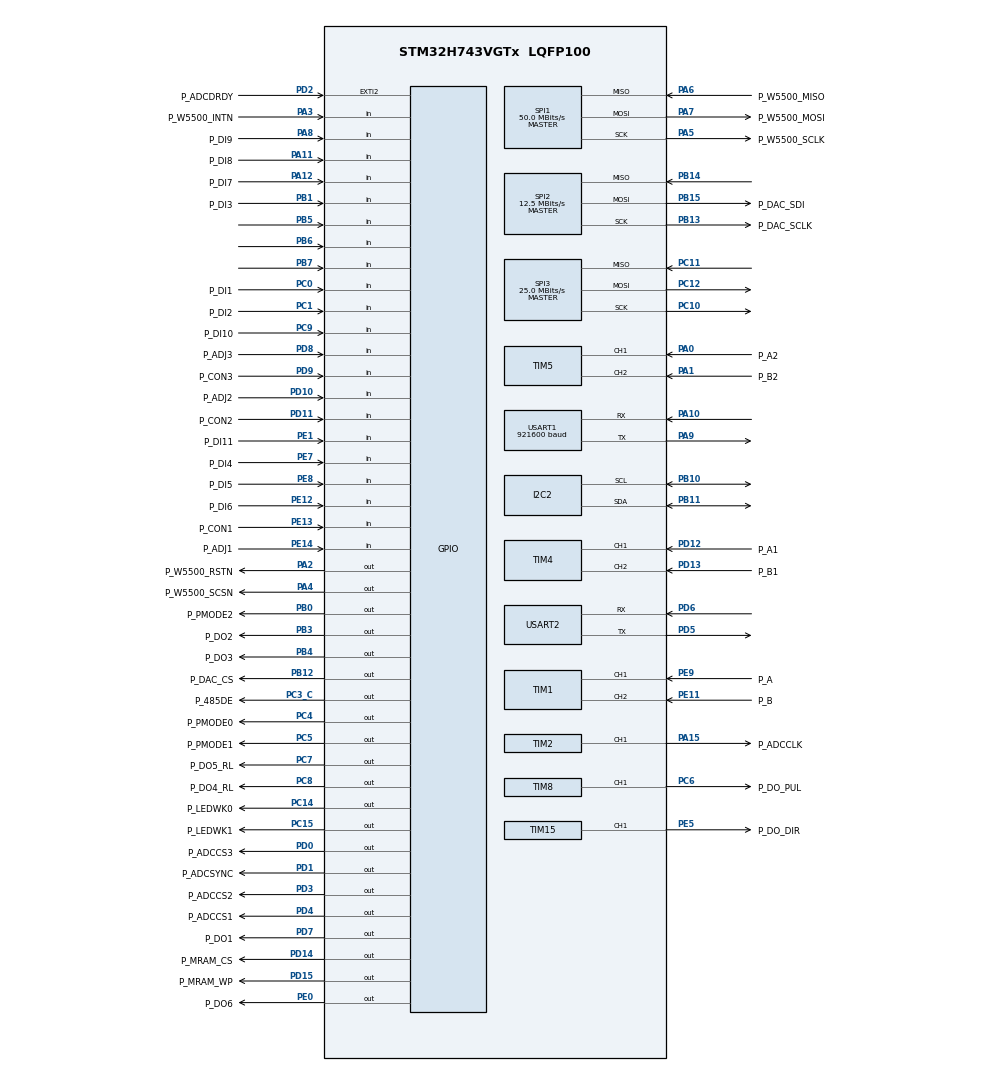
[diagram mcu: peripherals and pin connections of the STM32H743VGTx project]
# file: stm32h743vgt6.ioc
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CORTEX_M7.CPU_DCache=Disabled
CORTEX_M7.CPU_ICache=Disabled
CORTEX_M7.MPU_Control=MPU_PRIVILEGED_DEFAULT
CORTEX_M7.default_mode_Activation=1
FREERTOS.BinarySemaphores01=cs5552Sem,Dynamic,NULL,Available
FREERTOS.MEMORY_ALLOCATION=0
FREERTOS.Mutexes01=Controller_statusMutex,Dynamic,NULL;pgMutex,Dynamic,NULL;moveparaMutex,Dynamic,NULL
FREERTOS.Queues01=lpusTANQueue,16,uint16_t,0,Dynamic,NULL,NULL
FREERTOS.Tasks01=defaultTask,0,128,StartDefaultTask,Default,NULL,Dynamic,NULL,NULL;loopTask,3,2048,LoopTask,Default,NULL,Dynamic,NULL,NULL;watchdogTask,-2,128,WatchdogTask,Default,NULL,Dynamic,NULL,NULL;comTask,0,512,CommuicationTask,Default,NULL,Dynamic,NULL,NULL;waveTask,2,256,WaveTask,Default,NULL,Dynamic,NULL,NULL;ethernetTask,0,1024,EthernetTask,Default,NULL,Dynamic,NULL,NULL;cdatatranstask,0,256,CDataTransTask,Default,NULL,Dynamic,NULL,NULL;eepromTask,-2,512,EepromTask,Default,NULL,Dynamic,NULL,NULL
FREERTOS.configGENERATE_RUN_TIME_STATS=1
FREERTOS.configIDLE_SHOULD_YIELD=0
FREERTOS.configMAX_PRIORITIES=32
FREERTOS.configTOTAL_HEAP_SIZE=32768
FREERTOS.configUSE_STATS_FORMATTING_FUNCTIONS=1
FREERTOS.configUSE_TRACE_FACILITY=1
I2C2.Timing=0x10C0ECFF
Mcu.Family=STM32H7
Mcu.Name=STM32H743VGTx
Mcu.Package=LQFP100
NVIC.PriorityGroup=NVIC_PRIORITYGROUP_4
NVIC.TIM16_IRQn=true\:5\:0\:true\:false\:true\:true\:true\:true\:true
NVIC.TIM17_IRQn=true\:5\:0\:true\:false\:true\:true\:true\:true\:true
NVIC.TIM6_DAC_IRQn=true\:5\:0\:false\:false\:true\:true\:true\:true\:true
NVIC.TIM7_IRQn=true\:15\:0\:true\:false\:true\:false\:false\:true\:true
NVIC.TIM8_CC_IRQn=true\:5\:0\:false\:false\:true\:true\:true\:true\:true
NVIC.TimeBase=TIM7_IRQn
NVIC.TimeBaseIP=TIM7
NVIC.USART2_IRQn=true\:5\:0\:false\:false\:true\:true\:true\:true\:true
PA0.GPIO_Label=P_A2
PA0.Signal=S_TIM5_CH1
PA1.GPIO_Label=P_B2
PA1.Signal=S_TIM5_CH2
PA10.Mode=Asynchronous
PA10.Signal=USART1_RX
PA11.GPIO_Label=P_DI8
PA11.Signal=GPIO_Input
PA12.GPIO_Label=P_DI7
PA12.Signal=GPIO_Input
PA13\ (JTMS/SWDIO).Mode=Serial_Wire
PA13\ (JTMS/SWDIO).Signal=DEBUG_JTMS-SWDIO
PA14\ (JTCK/SWCLK).Mode=Serial_Wire
PA14\ (JTCK/SWCLK).Signal=DEBUG_JTCK-SWCLK
PA15\ (JTDI).GPIO_Label=P_ADCCLK
PA15\ (JTDI).Signal=S_TIM2_CH1_ETR
PA2.GPIO_Label=P_W5500_RSTN
PA2.Signal=GPIO_Output
PA3.GPIO_Label=P_W5500_INTN
PA3.Signal=GPIO_Input
PA4.GPIO_Label=P_W5500_SCSN
PA4.Signal=GPIO_Output
PA5.GPIO_Label=P_W5500_SCLK
PA5.GPIO_Speed=GPIO_SPEED_FREQ_VERY_HIGH
PA5.Mode=Full_Duplex_Master
PA5.Signal=SPI1_SCK
PA6.GPIO_Label=P_W5500_MISO
PA6.GPIO_Speed=GPIO_SPEED_FREQ_VERY_HIGH
PA6.Mode=Full_Duplex_Master
PA6.Signal=SPI1_MISO
PA7.GPIO_Label=P_W5500_MOSI
PA7.GPIO_Speed=GPIO_SPEED_FREQ_VERY_HIGH
PA7.Mode=Full_Duplex_Master
PA7.Signal=SPI1_MOSI
PA8.GPIO_Label=P_DI9
PA8.Signal=GPIO_Input
PA9.Mode=Asynchronous
PA9.Signal=USART1_TX
PB0.GPIO_Label=P_PMODE2
PB0.Signal=GPIO_Output
PB1.GPIO_Label=P_DI3
PB1.Signal=GPIO_Input
PB10.GPIO_Speed=GPIO_SPEED_FREQ_HIGH
PB10.Mode=I2C
PB10.Signal=I2C2_SCL
PB11.GPIO_Speed=GPIO_SPEED_FREQ_HIGH
PB11.Mode=I2C
PB11.Signal=I2C2_SDA
PB12.GPIO_Label=P_DAC_CS
PB12.GPIO_Speed=GPIO_SPEED_FREQ_HIGH
PB12.PinState=GPIO_PIN_SET
PB12.Signal=GPIO_Output
PB13.GPIO_Label=P_DAC_SCLK
PB13.Mode=Full_Duplex_Master
PB13.Signal=SPI2_SCK
PB14.Mode=Full_Duplex_Master
PB14.Signal=SPI2_MISO
PB15.GPIO_Label=P_DAC_SDI
PB15.Mode=Full_Duplex_Master
PB15.Signal=SPI2_MOSI
PB3\ (JTDO/TRACESWO).GPIO_Label=P_DO2
PB3\ (JTDO/TRACESWO).Signal=GPIO_Output
PB4\ (NJTRST).GPIO_Label=P_DO3
PB4\ (NJTRST).Signal=GPIO_Output
PB5.Signal=GPIO_Input
PB6.Signal=GPIO_Input
PB7.Signal=GPIO_Input
PC0.GPIO_Label=P_DI1
PC0.Signal=GPIO_Input
PC1.GPIO_Label=P_DI2
PC1.Signal=GPIO_Input
PC10.Mode=Full_Duplex_Master
PC10.Signal=SPI3_SCK
PC11.Mode=Full_Duplex_Master
PC11.Signal=SPI3_MISO
PC12.Mode=Full_Duplex_Master
PC12.Signal=SPI3_MOSI
PC14-OSC32_IN\ (OSC32_IN).GPIO_Label=P_LEDWK0
PC14-OSC32_IN\ (OSC32_IN).Signal=GPIO_Output
PC15-OSC32_OUT\ (OSC32_OUT).GPIO_Label=P_LEDWK1
PC15-OSC32_OUT\ (OSC32_OUT).Signal=GPIO_Output
PC3_C.GPIO_Label=P_485DE
PC3_C.Signal=GPIO_Output
PC4.GPIO_Label=P_PMODE0
PC4.Signal=GPIO_Output
PC5.GPIO_Label=P_PMODE1
PC5.GPIO_PuPd=GPIO_PULLUP
PC5.PinState=GPIO_PIN_SET
PC5.Signal=GPIO_Output
PC6.GPIO_Label=P_DO_PUL
PC6.GPIO_Speed=GPIO_SPEED_FREQ_VERY_HIGH
PC6.Signal=S_TIM8_CH1
PC7.GPIO_Label=P_DO5_RL
PC7.Signal=GPIO_Output
PC8.GPIO_Label=P_DO4_RL
PC8.Signal=GPIO_Output
PC9.GPIO_Label=P_DI10
PC9.Signal=GPIO_Input
PD0.GPIO_Label=P_ADCCS3
PD0.GPIO_Speed=GPIO_SPEED_FREQ_HIGH
PD0.PinState=GPIO_PIN_SET
PD0.Signal=GPIO_Output
PD1.GPIO_Label=P_ADCSYNC
PD1.Signal=GPIO_Output
PD10.GPIO_Label=P_ADJ2
PD10.Signal=GPIO_Input
PD11.GPIO_Label=P_CON2
PD11.Signal=GPIO_Input
PD12.GPIO_Label=P_A1
PD12.Signal=S_TIM4_CH1
PD13.GPIO_Label=P_B1
PD13.Signal=S_TIM4_CH2
PD14.GPIO_Label=P_MRAM_CS
PD14.GPIO_Speed=GPIO_SPEED_FREQ_HIGH
PD14.PinState=GPIO_PIN_SET
PD14.Signal=GPIO_Output
PD15.GPIO_Label=P_MRAM_WP
PD15.GPIO_Speed=GPIO_SPEED_FREQ_HIGH
PD15.PinState=GPIO_PIN_SET
PD15.Signal=GPIO_Output
PD2.GPIO_Label=P_ADCDRDY
PD2.GPIO_ModeDefaultEXTI=GPIO_MODE_IT_FALLING
PD2.Signal=GPXTI2
PD3.GPIO_Label=P_ADCCS2
PD3.GPIO_Speed=GPIO_SPEED_FREQ_HIGH
PD3.PinState=GPIO_PIN_SET
PD3.Signal=GPIO_Output
PD4.GPIO_Label=P_ADCCS1
PD4.GPIO_Speed=GPIO_SPEED_FREQ_HIGH
PD4.PinState=GPIO_PIN_SET
PD4.Signal=GPIO_Output
PD5.Mode=Asynchronous
PD5.Signal=USART2_TX
PD6.Mode=Asynchronous
PD6.Signal=USART2_RX
PD7.GPIO_Label=P_DO1
PD7.Signal=GPIO_Output
PD8.GPIO_Label=P_ADJ3
PD8.Signal=GPIO_Input
PD9.GPIO_Label=P_CON3
PD9.Signal=GPIO_Input
PE0.GPIO_Label=P_DO6
PE0.Signal=GPIO_Output
PE1.GPIO_Label=P_DI11
PE1.GPIO_PuPd=GPIO_PULLUP
PE1.Signal=GPIO_Input
PE11.GPIO_Label=P_B
PE11.Signal=S_TIM1_CH2
PE12.GPIO_Label=P_DI6
PE12.Signal=GPIO_Input
PE13.GPIO_Label=P_CON1
PE13.Signal=GPIO_Input
PE14.GPIO_Label=P_ADJ1
PE14.Signal=GPIO_Input
PE5.GPIO_Label=P_DO_DIR
PE5.GPIO_Speed=GPIO_SPEED_FREQ_VERY_HIGH
PE5.Signal=S_TIM15_CH1
PE7.GPIO_Label=P_DI4
PE7.Signal=GPIO_Input
PE8.GPIO_Label=P_DI5
PE8.Signal=GPIO_Input
PE9.GPIO_Label=P_A
PE9.Signal=S_TIM1_CH1
PH0-OSC_IN\ (PH0).Mode=HSE-External-Oscillator
PH0-OSC_IN\ (PH0).Signal=RCC_OSC_IN
PH1-OSC_OUT\ (PH1).Mode=HSE-External-Oscillator
PH1-OSC_OUT\ (PH1).Signal=RCC_OSC_OUT
ProjectManager.HeapSize=0x1000
ProjectManager.StackSize=0x1000
ProjectManager.TargetToolchain=MDK-ARM V5
RCC.ADCFreq_Value=16125000
RCC.APB1Freq_Value=100000000
RCC.APB2Freq_Value=100000000
RCC.APB3Freq_Value=100000000
RCC.APB4Freq_Value=100000000
RCC.CortexFreq_Value=200000000
RCC.D1PPRE=RCC_APB3_DIV2
RCC.D2PPRE1=RCC_APB1_DIV2
RCC.D2PPRE2=RCC_APB2_DIV2
RCC.D3PPRE=RCC_APB4_DIV2
RCC.DIVM1=1
RCC.DIVN1=50
RCC.HCLKFreq_Value=200000000
RCC.HSE_VALUE=8000000
RCC.PLL2FRACN=0
RCC.PLL3FRACN=0
RCC.PLLFRACN=0
RCC.PLLSourceVirtual=RCC_PLLSOURCE_HSE
RCC.PWR_Regulator_Voltage_Scale=PWR_REGULATOR_VOLTAGE_SCALE0
RCC.ProductRev=revV
RCC.SYSCLKFreq_VALUE=200000000
RCC.SYSCLKSource=RCC_SYSCLKSOURCE_PLLCLK
RCC.SupplySource=PWR_LDO_SUPPLY
RCC.USBFreq_Value=200000000
SH.S_TIM15_CH1.0=TIM15_CH1,PWM Generation1 CH1
SH.S_TIM1_CH1.0=TIM1_CH1,Encoder_Interface
SH.S_TIM1_CH2.0=TIM1_CH2,Encoder_Interface
SH.S_TIM2_CH1_ETR.0=TIM2_CH1,PWM Generation1 CH1
SH.S_TIM4_CH1.0=TIM4_CH1,Encoder_Interface
SH.S_TIM4_CH2.0=TIM4_CH2,Encoder_Interface
SH.S_TIM5_CH1.0=TIM5_CH1,Encoder_Interface
SH.S_TIM5_CH2.0=TIM5_CH2,Encoder_Interface
SH.S_TIM8_CH1.0=TIM8_CH1,PWM Generation1 CH1
SPI1.BaudRatePrescaler=SPI_BAUDRATEPRESCALER_4
SPI1.CalculateBaudRate=50.0 MBits/s
SPI1.DataSize=SPI_DATASIZE_8BIT
SPI1.Direction=SPI_DIRECTION_2LINES
SPI1.Mode=SPI_MODE_MASTER
SPI1.NSSPMode=SPI_NSS_PULSE_DISABLE
SPI1.VirtualType=VM_MASTER
SPI2.BaudRatePrescaler=SPI_BAUDRATEPRESCALER_16
SPI2.CalculateBaudRate=12.5 MBits/s
SPI2.DataSize=SPI_DATASIZE_8BIT
SPI2.Direction=SPI_DIRECTION_2LINES
SPI2.Mode=SPI_MODE_MASTER
SPI2.VirtualType=VM_MASTER
SPI3.BaudRatePrescaler=SPI_BAUDRATEPRESCALER_8
SPI3.CalculateBaudRate=25.0 MBits/s
SPI3.DataSize=SPI_DATASIZE_8BIT
SPI3.Direction=SPI_DIRECTION_2LINES
SPI3.Mode=SPI_MODE_MASTER
SPI3.VirtualType=VM_MASTER
TIM1.EncoderMode=TIM_ENCODERMODE_TI12
TIM13.AutoReloadPreload=TIM_AUTORELOAD_PRELOAD_ENABLE
TIM13.Prescaler=200-1
TIM14.AutoReloadPreload=TIM_AUTORELOAD_PRELOAD_ENABLE
TIM14.Period=200-1
TIM15.Channel-PWM\ Generation1\ CH1=TIM_CHANNEL_1
TIM15.Period=10000-1
TIM15.Pulse-PWM\ Generation1\ CH1=5000
TIM16.Period=100-1
TIM16.Prescaler=1000-1
TIM17.Period=10-1
TIM17.Prescaler=1000-1
TIM2.Channel-PWM\ Generation1\ CH1=TIM_CHANNEL_1
TIM2.Period=38-1
TIM2.Pulse-PWM\ Generation1\ CH1=19
TIM4.EncoderMode=TIM_ENCODERMODE_TI12
TIM6.AutoReloadPreload=TIM_AUTORELOAD_PRELOAD_ENABLE
TIM6.Period=100-1
TIM6.Prescaler=1000-1
TIM8.Channel-PWM\ Generation1\ CH1=TIM_CHANNEL_1
TIM8.Period=10000-1
TIM8.Pulse-PWM\ Generation1\ CH1=5000
USART1.BaudRate=921600
USART1.VirtualMode-Asynchronous=VM_ASYNC
USART2.VirtualMode-Asynchronous=VM_ASYNC
VP_FREERTOS_VS_CMSIS_V1.Mode=CMSIS_V1
VP_MEMORYMAP_VS_MEMORYMAP.Mode=CurAppReg
VP_SYS_VS_tim7.Mode=TIM7
VP_TIM13_VS_ClockSourceINT.Mode=Enable_Timer
VP_TIM14_VS_ClockSourceINT.Mode=Enable_Timer
VP_TIM15_VS_ClockSourceINT.Mode=Internal
VP_TIM16_VS_ClockSourceINT.Mode=Enable_Timer
VP_TIM17_VS_ClockSourceINT.Mode=Enable_Timer
VP_TIM2_VS_ClockSourceINT.Mode=Internal
VP_TIM6_VS_ClockSourceINT.Mode=Enable_Timer
VP_TIM8_VS_ClockSourceINT.Mode=Internal
board=custom

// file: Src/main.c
/* USER CODE BEGIN Header */
/**
  ******************************************************************************
  * @file           : main.c
  * @brief          : Main program body
  ******************************************************************************
  * @attention
  *
  * Copyright (c) 2023 STMicroelectronics.
  * All rights reserved.
  *
  * This software is licensed under terms that can be found in the LICENSE file
  * in the root directory of this software component.
  * If no LICENSE file comes with this software, it is provided AS-IS.
  *
  ******************************************************************************
  */
/* USER CODE END Header */
#include "main.h"
#include "cmsis_os.h"
#include "i2c.h"
#include "spi.h"
#include "tim.h"
#include "usart.h"
#include "gpio.h"

/* USER CODE BEGIN Includes */
#include "RS485.h"
#include "ETHw5500.h"
#include "Servo_Driver.h"
#include "myFifo.h"
#include "Encoder.h"
#include "gParameter.h"
#include "Eeprom_manage.h"
#include "mram_manage.h"
#include "td.h"
#include "pid.h"
#include <elog.h>
#include "MRAM.h"
#include "sensor.h"
#include "adrc.h"
#include "modbus_slave.h"
#include "filter.h"

// #include "delay.h"   // Retired software-SPI delay helper from the old ADC path.
// #include "io_spi.h"  // Retired software-SPI GPIO helper from the old ADC path.
#include "CS5552.h"

/* USER CODE END Includes */

/* USER CODE BEGIN PD */
#define FIRMWAREVERSION "1.16.7"
/* USER CODE END PD */

/* USER CODE BEGIN PV */
uint8_t test_check = 0;
/* USER CODE END PV */

void SystemClock_Config(void);
static void MPU_Config(void);
void MX_FREERTOS_Init(void);
/* USER CODE BEGIN PFP */
extern void DIFuncMap_init(void);
extern osSemaphoreId cs5552SemHandle;
extern volatile uint32_t tim6SignalCounter;
extern volatile uint8_t tim6PrintFlag;
/* USER CODE END PFP */

/* USER CODE BEGIN 0 */
/* Fun_111 */
void hardwareInit(void){
  //HAL_TIM_PWM_Start_IT(&htim8,TIM_CHANNEL_1);
  MRAM_CS_HIGH();
  //Servo init
  modFclkNumberPULSEInit(1000);
	Servo_PWM_Disable(PULSE);
#if (ServoPr007 == 0 || ServoPr007 == 1 || ServoPr007 == 2)
	Servo_PWM_Enable(DIR);
#else
	Servo_DIR_GPIO_Init();
#endif
  //485 init
  modbusInit();
  RS485_init(&huart2);
  // ADC init
  CS5552_CompatInit(&cs5552_compat_ctx);
  //Eth fifo init
	fifo_init(&rev_fifo);
  //Encoder init
	Encoder_Init();
}

/* Fun_112 */
void softwareInit(void){
  //sensor calibrate function init
  sensorCalibrateFuncInit();
  //Work State and Mode init
  workStateDefaultInit(&ws);
  workModeDefaultInit(&wm);
  //para init
  parameter_default_init();
	sendata_default_init();
  storageParaDefaultInit();
  mramInit();
  servoParamCalcu(&servoParam);
  //Eth init
	ETHw5500_init();
  //sensor read when system init
  eepromSensorReadInit(&sensorCheck);
  encoderCountInit(pose.code,0,0,&encoder);
  //while(1);
	//sync application layer sensor data
  senDateSync(SenData,&AL);
  //senor zero code init
  sensorZeroCodeInit();
  //init td filter
  create_TD(&load_td,10000);
  //pos init
	pidInitPos();
  pidInitLoad();
  pidInitExt();
  //di fucntion map
  DIFuncMap_init();
  //update the adrc variable
  poseCalcu();
  //update the pose once
  adrcInit(&leso,pose.orig);
  //manualBox init
  manualBoxInit();
  //update work state initState
  ws.init = initScomplete;
  //timer counter init
	HAL_TIM_Base_Start_IT(&htim6);
  HAL_TIM_Base_Start_IT(&htim16);
}

/* Fun_113 */
void firmwareVersionShown(void){
  printf("**********  Firmware Version:%s  **********\r\n",FIRMWAREVERSION);
}
/* USER CODE END 0 */

int main(void)
{

  /* USER CODE BEGIN 1 */
	// uint8_t err=0;
	// uint8_t send_buf_MRAM[10]={7,1,0x0A,8,6,0,8,1,0x0F,9};
	// uint8_t recv_buf_MRAM[10];
	// uint8_t i=0;
  // uint32_t counterUs = 0;
  /* USER CODE END 1 */

  /* MPU Configuration--------------------------------------------------------*/
  MPU_Config();

  /* MCU Configuration--------------------------------------------------------*/

  /* Reset of all peripherals, Initializes the Flash interface and the Systick. */
  HAL_Init();

  /* Configure the system clock */
  SystemClock_Config();

  /* Initialize all configured peripherals */
  MX_GPIO_Init();
  MX_I2C2_Init();
  MX_SPI1_Init();
  MX_SPI2_Init();
  MX_SPI3_Init();
  MX_TIM1_Init();
  MX_TIM2_Init();
  MX_TIM4_Init();
  MX_TIM5_Init();
  MX_TIM6_Init();
  MX_TIM8_Init();
  MX_TIM13_Init();
  MX_TIM14_Init();
  MX_TIM15_Init();
  MX_TIM16_Init();
  MX_TIM17_Init();
  MX_USART1_UART_Init();
  MX_USART2_UART_Init();
  /* USER CODE BEGIN 2 */
  printf("System Clock:%lu Hz\r\n", HAL_RCC_GetSysClockFreq());
  hardwareInit();
  softwareInit();
  HAL_TIM_Base_Start(&htim13);
  //firmwareVersionShown();

  /* USER CODE END 2 */

  /* Call init function for freertos objects (in cmsis_os2.c) */
  MX_FREERTOS_Init();

  /* Start scheduler */
  osKernelStart();

  /* We should never get here as control is now taken by the scheduler */

  /* Infinite loop */
  /* USER CODE BEGIN WHILE */
  while (1)
  {
    // delay_us(100000);
    // printf("delay_us!\r\n");
    /* USER CODE END WHILE */

  }
}

void SystemClock_Config(void)
{
  RCC_OscInitTypeDef RCC_OscInitStruct = {0};
  RCC_ClkInitTypeDef RCC_ClkInitStruct = {0};

  /** Supply configuration update enable
  */
  HAL_PWREx_ConfigSupply(PWR_LDO_SUPPLY);

  /** Configure the main internal regulator output voltage
  */
  __HAL_PWR_VOLTAGESCALING_CONFIG(PWR_REGULATOR_VOLTAGE_SCALE0);

  while(!__HAL_PWR_GET_FLAG(PWR_FLAG_VOSRDY)) {}

  /** Initializes the RCC Oscillators according to the specified parameters
  * in the RCC_OscInitTypeDef structure.
  */
  RCC_OscInitStruct.OscillatorType = RCC_OSCILLATORTYPE_HSE;
  RCC_OscInitStruct.HSEState = RCC_HSE_ON;
  RCC_OscInitStruct.PLL.PLLState = RCC_PLL_ON;
  RCC_OscInitStruct.PLL.PLLSource = RCC_PLLSOURCE_HSE;
  RCC_OscInitStruct.PLL.PLLM = 1;
  RCC_OscInitStruct.PLL.PLLN = 50;
  RCC_OscInitStruct.PLL.PLLP = 2;
  RCC_OscInitStruct.PLL.PLLQ = 2;
  RCC_OscInitStruct.PLL.PLLR = 2;
  RCC_OscInitStruct.PLL.PLLRGE = RCC_PLL1VCIRANGE_3;
  RCC_OscInitStruct.PLL.PLLVCOSEL = RCC_PLL1VCOWIDE;
  RCC_OscInitStruct.PLL.PLLFRACN = 0;
  if (HAL_RCC_OscConfig(&RCC_OscInitStruct) != HAL_OK)
  {
    Error_Handler();
  }

  /** Initializes the CPU, AHB and APB buses clocks
  */
  RCC_ClkInitStruct.ClockType = RCC_CLOCKTYPE_HCLK|RCC_CLOCKTYPE_SYSCLK
                              |RCC_CLOCKTYPE_PCLK1|RCC_CLOCKTYPE_PCLK2
                              |RCC_CLOCKTYPE_D3PCLK1|RCC_CLOCKTYPE_D1PCLK1;
  RCC_ClkInitStruct.SYSCLKSource = RCC_SYSCLKSOURCE_PLLCLK;
  RCC_ClkInitStruct.SYSCLKDivider = RCC_SYSCLK_DIV1;
  RCC_ClkInitStruct.AHBCLKDivider = RCC_HCLK_DIV1;
  RCC_ClkInitStruct.APB3CLKDivider = RCC_APB3_DIV2;
  RCC_ClkInitStruct.APB1CLKDivider = RCC_APB1_DIV2;
  RCC_ClkInitStruct.APB2CLKDivider = RCC_APB2_DIV2;
  RCC_ClkInitStruct.APB4CLKDivider = RCC_APB4_DIV2;

  if (HAL_RCC_ClockConfig(&RCC_ClkInitStruct, FLASH_LATENCY_2) != HAL_OK)
  {
    Error_Handler();
  }
}

/* USER CODE BEGIN 4 */
void HAL_GPIO_EXTI_Callback(uint16_t GPIO_Pin)
{
}
 uint16_t tim6us=0;

uint16_t pwmFinishcounter = 0;
void HAL_TIM_PWM_PulseFinishedCallback(TIM_HandleTypeDef *htim)
{
	if(htim->Instance == TIM8)
	{
    ++hal_output.pwmIntCounter;
    ++test.nr;
    // if(hal_output.pwmIntCounter >= hal_output.pwmCounter){
    //   hal_output.pwmIntCounter = 0;
    // }

  //   if(hal_output.pwmIntCounter >= hal_output.pwmCounter){
  //     HAL_TIM_PWM_Stop(&htim8,TIM_CHANNEL_1);
  //  }
	}
}
/* USER CODE END 4 */

 /* MPU Configuration */

void MPU_Config(void)
{
  MPU_Region_InitTypeDef MPU_InitStruct = {0};

  /* Disables the MPU */
  HAL_MPU_Disable();

  /** Initializes and configures the Region and the memory to be protected
  */
  MPU_InitStruct.Enable = MPU_REGION_ENABLE;
  MPU_InitStruct.Number = MPU_REGION_NUMBER0;
  MPU_InitStruct.BaseAddress = 0x0;
  MPU_InitStruct.Size = MPU_REGION_SIZE_4GB;
  MPU_InitStruct.SubRegionDisable = 0x87;
  MPU_InitStruct.TypeExtField = MPU_TEX_LEVEL0;
  MPU_InitStruct.AccessPermission = MPU_REGION_NO_ACCESS;
  MPU_InitStruct.DisableExec = MPU_INSTRUCTION_ACCESS_DISABLE;
  MPU_InitStruct.IsShareable = MPU_ACCESS_SHAREABLE;
  MPU_InitStruct.IsCacheable = MPU_ACCESS_NOT_CACHEABLE;
  MPU_InitStruct.IsBufferable = MPU_ACCESS_NOT_BUFFERABLE;

  HAL_MPU_ConfigRegion(&MPU_InitStruct);
  /* Enables the MPU */
  HAL_MPU_Enable(MPU_PRIVILEGED_DEFAULT);

}

void HAL_TIM_PeriodElapsedCallback(TIM_HandleTypeDef *htim)
{
  /* USER CODE BEGIN Callback 0 */
	if(htim->Instance==htim6.Instance)
	{
    if ((cs5552SemHandle != NULL) && (osKernelRunning() == 1))
    {
      osSemaphoreRelease(cs5552SemHandle);
    }
	}
  //2kHz for encoder collecting
  if(htim->Instance == TIM16){
    // 2 kHz encoder sampling: latch three encoder accumulators each 0.5 ms.
    Encoder_Get(Encoder0, &encoder);
    Encoder_Get(Encoder1, &encoder);
    Encoder_Get(Encoder2, &encoder);
    // Update raw code values used by position and big-deformation calculations.
    poseCodeCalculate_Int(&pose,encoder.count0);
    poseCodeCalculate_Int(&bigDeformationLower,encoder.count1);
    poseCodeCalculate_Int(&bigDeformationUpper,encoder.count2);
    // Update the position-speed code filter in interrupt context.
    poseSpeedFilter_Int(&filter_Int,&pose,&speedPose,10);
    // Software UTC time base follows the 0.5 ms encoder sampling period.
    AL.utcTime +=0.0005f;
  }else if(htim->Instance == TIM17){
    // FreeRTOS runtime statistics time base.
    FreeRTOSRunTimeTicks++;
  }
  /* USER CODE END Callback 0 */
  if (htim->Instance == TIM7)
  {
    HAL_IncTick();
  }
}

void Error_Handler(void)
{
  __disable_irq();
  while (1)
  {
  }
}

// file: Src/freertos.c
/* USER CODE BEGIN Header */
/**
  ******************************************************************************
  * File Name          : freertos.c
  * Description        : Code for freertos applications
  ******************************************************************************
  * @attention
  *
  * Copyright (c) 2023 STMicroelectronics.
  * All rights reserved.
  *
  * This software is licensed under terms that can be found in the LICENSE file
  * in the root directory of this software component.
  * If no LICENSE file comes with this software, it is provided AS-IS.
  *
  ******************************************************************************
  */
/* USER CODE END Header */

#include "FreeRTOS.h"
#include "task.h"
#include "main.h"
#include "cmsis_os.h"
#include "tim.h"

/* USER CODE BEGIN Includes */
#include "control.h"
#include "in_out.h"
#include "trackplaning.h"
#include "userdebug.h"
#include "RS485.h"
#include "ETHw5500.h"
#include "EthProtocol.h"
#include "usart.h"
#include "Servo_driver.h"
#include "posGenerator.h"
#include "gParameter.h"
#include "Encoder.h"
#include "communicate.h"
#include "Eeprom_manage.h"
#include "sensor.h"
#include "td.h"
#include "DI.h"
#include "lsm.h"
#include "pid.h"
#include <elog.h>
#include "mram_manage.h"
#include "adrc.h"
#include "CS5552.h"
// #include "CS553X.h"  // Legacy CS5530 header disabled during CS5552 migration.

/* USER CODE END Includes */

/* USER CODE BEGIN PD */
#define TIM6_PRINT_10MS_INTERVAL_MS  10U
#define TIM6_PRINT_1S_INTERVAL_MS    1000U

/* USER CODE END PD */

/* USER CODE BEGIN Variables */
uint32_t loop_t=0;
uint16_t time13Count = 0;
uint32_t okCounter = 0;
volatile uint32_t tim6SignalCounter = 0;
volatile uint8_t tim6PrintFlag = 0;
/* USER CODE END Variables */
osThreadId defaultTaskHandle;
osThreadId loopTaskHandle;
osThreadId watchdogTaskHandle;
osThreadId comTaskHandle;
osThreadId waveTaskHandle;
osThreadId ethernetTaskHandle;
osThreadId cdatatranstaskHandle;
osThreadId eepromTaskHandle;
osMessageQId lpusTANQueueHandle;
osMutexId Controller_statusMutexHandle;
osMutexId pgMutexHandle;
osMutexId moveparaMutexHandle;
osSemaphoreId cs5552SemHandle;

/* USER CODE BEGIN FunctionPrototypes */
void Controller_status_update(uint16_t status_all);//???????????????????±?????????§???????è??????ì????????????????????????  ?????????ì????????è???????????è??????°????????????????????
static uint32_t Tim6GetUpdateFrequencyHz(void);
static uint32_t Tim6GetIntervalCount(uint32_t interval_ms, uint32_t update_hz);
/* USER CODE END FunctionPrototypes */

void StartDefaultTask(void const * argument);
void LoopTask(void const * argument);
void WatchdogTask(void const * argument);
void CommuicationTask(void const * argument);
void WaveTask(void const * argument);
void EthernetTask(void const * argument);
void CDataTransTask(void const * argument);
void EepromTask(void const * argument);

void MX_FREERTOS_Init(void); /* (MISRA C 2004 rule 8.1) */

/* Hook prototypes */
void configureTimerForRunTimeStats(void);
unsigned long getRunTimeCounterValue(void);

/* USER CODE BEGIN 1 */
static uint32_t Tim6GetUpdateFrequencyHz(void)
{
  uint32_t pclk1_hz = HAL_RCC_GetPCLK1Freq();
  uint32_t tim6_clock_hz = pclk1_hz;
  uint32_t timer_divisor;

  if (HAL_RCC_GetHCLKFreq() != pclk1_hz)
  {
    tim6_clock_hz *= 2u;
  }

  timer_divisor = (htim6.Init.Prescaler + 1u) * (htim6.Init.Period + 1u);
  if (timer_divisor == 0u)
  {
    return 1u;
  }

  return tim6_clock_hz / timer_divisor;
}

static uint32_t Tim6GetIntervalCount(uint32_t interval_ms, uint32_t update_hz)
{
  uint32_t interval_count;

  interval_count = (update_hz * interval_ms + 999u) / 1000u;
  if (interval_count == 0u)
  {
    interval_count = 1u;
  }

  return interval_count;
}

/* Functions needed when configGENERATE_RUN_TIME_STATS is on */
__weak void configureTimerForRunTimeStats(void)
{

}

__weak unsigned long getRunTimeCounterValue(void)
{
return 0;
}
/* USER CODE END 1 */

void MX_FREERTOS_Init(void) {
  /* USER CODE BEGIN Init */
  Static_Set_Output_Log_Format();
  /* USER CODE END Init */
  /* Create the mutex(es) */
  /* definition and creation of Controller_statusMutex */
  osMutexDef(Controller_statusMutex);
  Controller_statusMutexHandle = osMutexCreate(osMutex(Controller_statusMutex));

  /* definition and creation of pgMutex */
  osMutexDef(pgMutex);
  pgMutexHandle = osMutexCreate(osMutex(pgMutex));

  /* definition and creation of moveparaMutex */
  osMutexDef(moveparaMutex);
  moveparaMutexHandle = osMutexCreate(osMutex(moveparaMutex));

  /* Create the semaphores(s) */
  /* definition and creation of cs5552Sem */
  osSemaphoreDef(cs5552Sem);
  cs5552SemHandle = osSemaphoreCreate(osSemaphore(cs5552Sem), 1);

  /* Create the queue(s) */
  /* definition and creation of lpusTANQueue */
  osMessageQDef(lpusTANQueue, 16, uint16_t);
  lpusTANQueueHandle = osMessageCreate(osMessageQ(lpusTANQueue), NULL);

  /* Create the thread(s) */
  /* definition and creation of defaultTask */
  osThreadDef(defaultTask, StartDefaultTask, osPriorityRealtime, 0, 128);
  defaultTaskHandle = osThreadCreate(osThread(defaultTask), NULL);

  /* definition and creation of loopTask */
  osThreadDef(loopTask, LoopTask, osPriorityRealtime, 0, 2048);
  loopTaskHandle = osThreadCreate(osThread(loopTask), NULL);

  /* definition and creation of watchdogTask */
  osThreadDef(watchdogTask, WatchdogTask, osPriorityLow, 0, 128);
  watchdogTaskHandle = osThreadCreate(osThread(watchdogTask), NULL);

  /* definition and creation of comTask */
  osThreadDef(comTask, CommuicationTask, osPriorityNormal, 0, 512);
  comTaskHandle = osThreadCreate(osThread(comTask), NULL);

  /* definition and creation of waveTask */
  osThreadDef(waveTask, WaveTask, osPriorityHigh, 0, 256);
  waveTaskHandle = osThreadCreate(osThread(waveTask), NULL);

  /* definition and creation of ethernetTask */
  osThreadDef(ethernetTask, EthernetTask, osPriorityNormal, 0, 1024);
  ethernetTaskHandle = osThreadCreate(osThread(ethernetTask), NULL);

  /* definition and creation of cdatatranstask */
  osThreadDef(cdatatranstask, CDataTransTask, osPriorityNormal, 0, 256);
  cdatatranstaskHandle = osThreadCreate(osThread(cdatatranstask), NULL);

  /* definition and creation of eepromTask */
  osThreadDef(eepromTask, EepromTask, osPriorityLow, 0, 512);
  eepromTaskHandle = osThreadCreate(osThread(eepromTask), NULL);

}

void StartDefaultTask(void const * argument)
{
  /* USER CODE BEGIN StartDefaultTask */
  uint32_t tim6UpdateHz = Tim6GetUpdateFrequencyHz();
  uint32_t tim6Print10msCount = Tim6GetIntervalCount(TIM6_PRINT_10MS_INTERVAL_MS, tim6UpdateHz);
  uint32_t tim6Print1sCount = Tim6GetIntervalCount(TIM6_PRINT_1S_INTERVAL_MS, tim6UpdateHz);

  /* Clear the initial token created by the binary semaphore. */
  osSemaphoreWait(cs5552SemHandle, 0);

  /* Infinite loop */
  for(;;)
  {
        if (osSemaphoreWait(cs5552SemHandle, osWaitForever) == osOK)
        {
          // taskENTER_CRITICAL();
          // HAL_GPIO_WritePin(P_ADCCS1_GPIO_Port, P_ADCCS1_Pin, GPIO_PIN_SET);

          CS5552_Tim6SampleAndFilter();
          MD_CODE_map(sensorCheck.MapNum);
          // HAL_GPIO_WritePin(P_ADCCS1_GPIO_Port, P_ADCCS1_Pin, GPIO_PIN_RESET);
          // taskEXIT_CRITICAL();
          tim6SignalCounter++;
          tim6PrintFlag = 1u;

          if ((tim6SignalCounter % tim6Print10msCount) == 0u)
          {
            printf("%.6f\r\n", g_voltage_filtered_ch0);
          }

          if (tim6SignalCounter >= tim6Print1sCount)
          {
            printf("-----%lu-----%lu-----\r\n",
                   (unsigned long)ch0_valid_sample_count,
                   (unsigned long)ch0_invalid_sample_count);
            ch0_valid_sample_count = 0u;
            ch0_invalid_sample_count = 0u;
            tim6SignalCounter = 0u;
          }
        }
  }
  /* USER CODE END StartDefaultTask */
}

void LoopTask(void const * argument)
{
  /* USER CODE BEGIN LoopTask */
	uint16_t i=0;
  uint8_t sensorcode_counter=0;
	//test_DynCycle_para_init();
  pidInitPos();
  pidInitLoad();
  pidInitExt();
	//DynCycle_planinit();
  /* Infinite loop */
  for(;;)
  {
	  // loop_t++;
	  // if(loop_t >= dyncycle_modify.t5+500)
	  // //if(loop_t >= dyncycle_normal.t3+100)
	  // {
		// pgdyn.waveform++;
		//   if(pgdyn.waveform > 5)
		// 	  pgdyn.waveform = 0;
		// loop_t =0;
		//   DynCycle_planinit();
	  // }
	  // pgdyn.pos=DynCycle_posgenerator(&pgdyn,loop_t);//test for dynCycle

    //eth heart beat watchdog
	  //ETH_HeartbeatWatchdog(&stateFlag.PC_ack_state,ETH_HEARTBEAT_THRESHOLD);

    //mointor work mode
    workModeMonitor(&wm,&ws);

	  EnableState_Update();//??è??????§???????è???????????¤????????????°??

    //openloop param update
	  openloop_parameters_update();

		//??è??????????????????§Sendata????????????°??
		if(mySemaphore.comm.sendataUpdate == 1)
		{
      log_i("sendata_update() run before");
			sendata_update();//?????????????????°???§?????????°??????????????????????? ????¤??????????????????????????§?????????????????????????????????????????§?????
			//??????????????EEPROM???????????????è???????????¤??????
      if(sensorConnector == ch0Pose)
        mySemaphore.mram.write_sendataPose = 1;
      else if(sensorConnector == ch1Bd)
        mySemaphore.mram.write_sendataBigDerformation = 1;
      else
        mySemaphore.eeprom.write_sendataOther = 1;

		}
		stateFlag.OpenDevice_state = Device_Open;
		if(stateFlag.OpenDevice_state == Device_Open)//Device_Open
		{
      if(++sensorcode_counter>=10)
      {
        sensorcode_counter=0;
        mySemaphore.mram.write_sensorcode = 1;
      }
			inputGetValue();
			inputMapping();
      //scram button == 0 stop srv
			if(stateFlag.DoPE_state == DoPE_On)//DoPE_On
			{
				switch(stateFlag.DoPESetCtrl)//DoPESetCtrl
				{
					case CtrlTRUE:
								controlLoop();
								if(i++ >= 100){i = 0;LEDlight_Tog();}
					break;
					case CtrlFALSE:

								svPWM.pos=0;
								if(i++ >= 1000){i = 0;LEDlight_Tog();}
					break;
				}
			}
			else
			{
				svPWM.pos = 0;
				svAO.pos = 0;
				if(i++ >= 2000){i = 0;LEDlight_Tog();}
			}

			outputMapping();
			outputControl();
		}
		else
		{
			LEDlight_Off();
		}
    osDelay(1);
  }
  /* USER CODE END LoopTask */
}

void WatchdogTask(void const * argument)
{
  /* USER CODE BEGIN WatchdogTask */
	uint16_t loopCounter = 0;
  /* Infinite loop */
  for(;;)
  {
	  if(loopCounter++ >= 20){
		  loopCounter = 0;
		 // log_i("monitor running");
	  }
	  //system reset
    if(mySemaphore.systemReset.reset == 1){
      stm32SoftReset();
    }

	  //Eth task monitor
	  if(taskMonitor.ethFood == 1){
		taskMonitor.ethFood = 0;
		taskMonitor.ethDog = 0;
	  }else{
		taskMonitor.ethDog++;
		  if(taskMonitor.ethDog >= 40){
			  taskMonitor.ethDog = 0;
			  log_e("Eth taskMonitor Trigger,Restart Eth task");
			//restart task
			if( ethernetTaskHandle != NULL )
			{
				vTaskDelete( ethernetTaskHandle );
				//Eth init
				ETHw5500_init();
				osThreadDef(ethernetTask, EthernetTask, osPriorityNormal, 0, 1024);
				ethernetTaskHandle = osThreadCreate(osThread(ethernetTask), NULL);
				log_i("Success Restart Eth task");
			}else{
				osThreadDef(ethernetTask, EthernetTask, osPriorityNormal, 0, 1024);
				ethernetTaskHandle = osThreadCreate(osThread(ethernetTask), NULL);
				log_i("Success Restart Eth task");

			}
		  }

	  }

	  //Comm task monitor
	  if(taskMonitor.commFood == 1){
		taskMonitor.commFood = 0;
		taskMonitor.commDog = 0;
	  }else{
		taskMonitor.commDog++;
		  if(taskMonitor.commDog >= 40){
			  taskMonitor.commDog = 0;
			  log_e("Comm taskMonitor Trigger,Restart Comm task");
			//restart task
			if( comTaskHandle != NULL )
			{
				vTaskDelete( comTaskHandle );
				osThreadDef(comTask, CommuicationTask, osPriorityLow, 0, 512);
				comTaskHandle = osThreadCreate(osThread(comTask), NULL);
				log_i("Success Restart Comm task");
			}else{
				osThreadDef(comTask, CommuicationTask, osPriorityLow, 0, 512);
				comTaskHandle = osThreadCreate(osThread(comTask), NULL);
				log_i("Success Restart Comm task");
			}

		  }

	  }

    osDelay(50);
  }
  /* USER CODE END WatchdogTask */
}

void CommuicationTask(void const * argument)
{
  /* USER CODE BEGIN CommuicationTask */
	uint16_t loopCounter = 0;
  portTASK_USES_FLOATING_POINT();
  /* Infinite loop */
  for(;;)
  {
	  taskMonitor.commFood = 1;
		ETH_Communicate_Process();
    // if(loopCounter % 300 == 0){
		//   RS485_test();
    // }
	  if(loopCounter++ >= 900){
		  loopCounter = 0;
		//log_d("CommuicationTask running normal");
	  }
    osDelay(1);
  }
  /* USER CODE END CommuicationTask */
}

/* USER CODE BEGIN Header_WaveTask */
extern void forceTareTestPrint(void);
void taskListPrint(char * buf){
  vTaskList(buf);
  printf("Task List\r\n");
  printf("Name\t\tState\tPriority\tStack\tNum\t\r\n");
  printf("%s", buf);
  printf("B:Block  R:Ready  D:Delete  S:suspend  X:running \r\n");
  vTaskGetRunTimeStats(buf);
  printf("Name\t\trunCount\t\tCPU_usage \r\n");
  printf("%s\r\n",buf);
}
uint8_t taskListBuffer[500];
/**
* @brief Function implementing the waveTask thread.
* @param argument: Not used
* @retval None
*/
/* USER CODE END Header_WaveTask */
void WaveTask(void const * argument)
{
  /* USER CODE BEGIN WaveTask */
	//static char buffer[1024] = {0};
  static uint32_t counter = 0;
  // static uint32_t counterInt = 0;
  /* Infinite loop */
  for(;;)
  {
    //printf("DB9.ADJ1.value:%d,DB9.ADJ2.value:%d,DB9.ADJ3.value:%d,cdatatrans.SensorKeyPressed:%d\r\n",DB9.ADJ1.value,DB9.ADJ2.value,DB9.ADJ3.value,cdatatrans.SensorKeyPressed);
    // printf("%d,%d,%d,%f,%f,%f,%d,%d,%d,%f\r\n",cs5530.Code[cs5530Channel1],cs5530.Code[cs5530Channel2],cs5530.Code[cs5530Channel3],
    //                               cs5530.Voltage[cs5530Channel1],cs5530.Voltage[cs5530Channel2],cs5530.Voltage[cs5530Channel3],
    //                               time13Count,okCounter,force.code,force.orig);

  counter++;
  if(counter >= 100){
      counter = 0;

      //printf("%d,%d,%f,%f,%f\r\n",bigDeformationLower.code,bigDeformationUpper.code,bigDeformationLower.orig,bigDeformationUpper.orig,bigDeformationSum.orig);
      //printf("PWM:%f\r\n",hal_output.PWM);
      //printf("workMode:%d,%d,%x,%x,%x,%x,%f,%f,%f\r\n",wm.now,wm.last,ws.moveReady,ws.emergency,ws.limitTypeWord,ws.paraConfig,extAllCtrlPara.Sft.UpperSft,extAllCtrlPara.Sft.LowerSft,strain1.filter);
      //printf("type:%d\r\n",manualBox.type);
      //printf("value:%d,fvalue:%f\r\n",AL.tare.value[ch4Load],AL.tare.fValue[ch4Load]);
    }
    // extern void rigidityLsmIdentify(uint16_t filter_depth,const float _xOrig,const float _yOrig);
    // rigidityLsmIdentify(100,pose.orig,force.filter);
    // rigidityUpdateRLS(&rigidityRLS,pose.orig,force.filter,0.95);
    //printf("%f,%f,%f,%f,%f,%f,%f\r\n",rigidityRLS.S_xx,rigidityRLS.S_xy,rigidityRLS.k,lsRigidity.k,lsRigidity.kFilter,lsRigidity.x_m,lsRigidity.y_m);

    // printf("%f,%d,%f,%d,%f,%f,%f,%f,%f,%f,%f\r\n",hal_output.PWM,pose.code,pose.orig,AL.openloopFrq,
    //   test.monitor1,test.monitor2,test.monitor3,test.monitor4,test.monitor5,test.monitor6,test.fclk );
//#define DEBUG_LOADCRTOL_250310
#ifdef DEBUG_LOADCRTOL_250310
  printf("%f,%f,%f,%f,%f,%f,%f,%d,%f,%f,%f,%f\r\n",
    pose.orig,
    pgLoad.st,
    force.filter,
    AL.loadCtrl.detaLoopCtrlOut,
    AL.loadCtrl.posLoopCtrlOut,
    svPWM.load,
    pid_load.out,
    posCtrlPeriod.real,
    speedForce.filter,
    pid_load.kiSeparate,
    pid_load.kpSeparate,
    lsRigidity.k);
#endif

//#define DEBUG_EXTCRTOL_250320
#ifdef DEBUG_EXTCRTOL_250320
  printf("%f,%f,%f,%f,%f,%f,%f,%d,%f,%f,%f,%f,%f,%f\r\n",
    pose.orig,
    pgExt.st,
    strain1.filter,
    AL.ext1Ctrl.detaLoopCtrlOut,
    AL.ext1Ctrl.posLoopCtrlOut,
    svPWM.ext,
    pid_ext.out,
    posCtrlPeriod.real,
    speedStrain.filter,
    pid_ext.kp,
    pid_ext.ki,
    pid_ext.out,
    pid_ext.err,
    pid_ext.setValue);
#endif

//#define DEBUG_POS_CALIBRATE_250110
#ifdef DEBUG_POS_CALIBRATE_250110
  printf("%d,%.6f,%d,%.15f,%f,%f,%f,%d,%d,%d\r\n",pose.code,pose.orig,sensorCalibrate.zeroCode[ch0Pose],AL.posCtrl.NominalSensitive,
                                   test.monitor1,test.monitor2,test.monitor3,test.monitorCode1,test.monitorCode2,test.index);
#endif

//#define DEBUG_LOAD_250108
#ifdef DEBUG_LOAD_250108
  printf("%f,%f,%f,%d,%f,%f,%f,%f,%f\r\n",pgLoad.st,force.filterTrans,force.filter,force.code,AL.tare.fValue[ch4Load],AL.loadCtrl.NominalSensitive,AL.loadCtrl.NominalValue,pid_load.kiSeparate,pid_load.kpSeparate);
#endif

//#define DEBUG_PULSE_250103
#ifdef DEBUG_PULSE_250103
  printf("%f,%f,%d,%d,%d\r\n",(pg.st-pose.orig),test.fclk,test.reloadVal,test.reloadValHalf,test.pcs);
#endif

//#define DEBUG_POSEXT
#ifdef DEBUG_POSEXT
  if((sign(posext.Destination)*(posext.Destination - force.filter) <= 0)
                && mySemaphore.move.pgInit == 0)
  printf("%f,%f,%d,%f\r\n",posext.Destination,force.filter,mySemaphore.move.pgInit,sign(posext.Destination)*(posext.Destination - force.filter));
#endif

//#define DEBUG_STRIAN
#ifdef DEBUG_STRIAN
  printf("%f,%f,%f,%d\r\n",pgExt.st,strain1.orig,strain1Lsm.filter,strain1.code);
#endif

//#define DEBUG_POSE_UP
#ifdef DEBUG_POSE_UP
    printf("%f,%f,%f,%f\r\n",pg.st,pose.orig,pg.vt,speedPose.filter);
#endif

//#define DEBUG_TASKLIST
#ifdef DEBUG_TASKLIST
  if(++countTaskList>=10){
    countTaskList = 0;
    taskListPrint((char *)taskListBuffer);
  }
#endif
//#define DEBUG_CRASH_241011
#ifdef DEBUG_CRASH_241011
    printf("%f,%f,%f,%f\r\n",svPWM.pos,pose.orig,force.filter,force.filterTrans);
#endif

#define DEBUG_LOAD_SENSOR
#ifdef DEBUG_LOAD_SENSOR
    // printf("%d,%f,%f,%f,%f,%d,%f,%f,%f,%d,%d\r\n",force.code,force.orig,force.filter,forceLsm.filter,force.filterTrans,AL.tare.value[ch4Load],AL.tare.fValue[ch4Load],
    //                     AL.loadCtrl.NominalSensitive,AL.loadCtrl.NominalValue,filterLen.loadLen,SenData[ch4Load].sensorIntgr);
#endif

//#define DEBUG_TEST
#ifdef DEBUG_TEST
    printf("%.10f,%.10f,%.10f,%d,%d\r\n",test.monitor1,test.monitor2,test.monitor3,test.monitorCode1,test.monitorCode2);
#endif

//#define DEUBG_PID_POS
#ifdef DEUBG_PID_POS
    printf("%f,%lf,%lf,%f,%f,%d,%d\r\n",AL.posCtrl.posLoopCtrlOut,leso.z2,leso.z1,pg.st_last,pose.orig,servoPulse.out,pid_pos.calcuRun);
    //printf("%lf,%lf,%lf,%f,%f,%f,%d,%d,",leso.u,leso.y,leso.e,hal_output.PWM,svPWM.pos,test.fclk,__HAL_TIM_GET_COUNTER(&htim8),test.esoCounter);
    //printf("%d,%f,%f\r\n",counterInt,force.filter,force.filterTrans);
    //printf("posCtrlPeriod.real %d vm:%f\r\n",posCtrlPeriod.real,pg.vm);
#endif // DEBUG

    //printf("%f,%f,%f,%f,%f,%d,%f \r\n",leso.z1,pg.st_last,pose.orig,leso.z2,svPWM.pos,AL.complete_state.flag,AL.servoOutput);
    //printf("%d,%d,%d,%d,%f\r\n",wm.now,wm.last,ws.emergency,ws.loopCtrl,speedPose.filter);
//#define DEBUG_LOAD
#ifdef DEBUG_LOAD
    printf("%f,%f,%f,%f,%f,%f,%f,%f,%f,%d,%d,%d,%d,%d,%d,%d\r\n",AL.loadCtrl.detaLoopCtrlOut,AL.loadCtrl.posLoopCtrlOut,AL.loadCtrl.speedLoopCtrlOut,force.filter,pgLoad.st_last,pgLoad.st_last-force.filter,svPWM.load,pose.orig,pg.st_last,hal_output.PWM,hal_output.pwmIntCounter,test.pcs,test.reloadVal,test.reloadValHalf,test.fclk,posCtrlPeriod.real);
#endif // DEBUG
//#define DEBUG1_9_2
#ifdef DEBUG1_9_2
    //printf("%f,%f,%f,%f,%f,%f,%f,%f,%d,%f,%f,%f,%d,%d,%d,%f,%f,%f,%f,%f,%d\r\n",pg.st_last,pose.orig,fhan.x1,fhan.x2,fhan.fh,pg.vt,svPWM.pos,leso.z2,tim6us,AL.servoOutput,forceLsm.filter,force.filter,hal_output.PWM,hal_output.pwmIntCounter,AL.complete_state.flag,pwms1,pwms2,pwms3,pid_pos.out,AL.posCtrl.posLoopCtrlOut,posCtrlPeriod.real);
    printf("%f,%f,%f,%f,%f,%d,%d,%f \r\n",pgLoad.st_last,force.filter,pg.st_last,pose.orig,svPWM.pos,hal_output.PWM,posCtrlPeriod.real,svPWM.pos * posCtrlPeriod.real / 1000.0);

#endif

//#define DEBUG1_9_4
#ifdef DEBUG1_9_4
    printf("%d,%d\r\n",SenData[ch4Load].sensorIntgr,SenData[ch0Pose].sensorIntgr);
#endif
    //forceTareTestPrint();
	  osDelay(10);
  }
  /* USER CODE END WaveTask */
}

void EthernetTask(void const * argument)
{
  /* USER CODE BEGIN EthernetTask */
  portTASK_USES_FLOATING_POINT();
	uint16_t loopCounter = 0;
  /* Infinite loop */
  for(;;)
  {
	  taskMonitor.ethFood = 1;

		ETHw5500_Func();
	  if(loopCounter++ >= 200){
		  loopCounter = 0;
		//log_d("EthernetTask running normal");
	  }
    //log_d("EthernetTask running normal");
    osDelay(5);
  }
  /* USER CODE END EthernetTask */
}

void CDataTransTask(void const * argument)
{
  /* USER CODE BEGIN CDataTransTask */
	// uint16_t loopCounter = 0;
  /* Infinite loop */
  for(;;)
  {
	if(stateFlag.OpenDevice_state == Device_Open)//Device_Open
	{
//		if(stateFlag.DoPE_state == DoPE_On)//DoPE_On
//		{
			if(stateFlag.DoPETransmitData == TRUE)
			{
				CurrentData_Fifo_Push();
        //printf("periodic data trans running\r\n");
			}
//		}
	}

	if(mySemaphore.comm.transperiodUpdate == 1)
	{
		SysPara.TransmitDataPeriod = commBuf.SysPara.TransmitDataPeriod;
		mySemaphore.mram.write_transmitdataperiod = 1;
		mySemaphore.comm.transperiodUpdate = 0;

	}
//	if(loopCounter++ >= 5){
//		loopCounter = 0;
//		log_d("CDataTransTask running normal");
//	  }
    osDelay(SysPara.TransmitDataPeriod);
  }
  /* USER CODE END CDataTransTask */
}

void EepromTask(void const * argument)
{
  /* USER CODE BEGIN EepromTask */
  uint16_t initWaitCounter = 0;
  /* Infinite loop */
  for(;;)
  {
    //DB9 senser Type Map corresponding SENSOR_CHANNEL
#if USE_DB9_CON
	  sensorTypeMap(&mySemaphore.db9);
#else
    //need wait 1s after power on
    if(initWaitCounter++ >= 100){
      initWaitCounter = 100;
      sensorConnectCheckByEeprom(&halDB9);
    }
#endif
    manualBoxTypeMonitor(&manualBox);
    mram_write_monitor(&mySemaphore.mram);
    eeprom_write_monitor(&mySemaphore.eeprom);
    // CS5552 compatibility recovery hook is currently disabled here.
  // CS5552_CompatResetMonitor(&cs5552_compat_ctx);

    osDelay(10);
  }
  /* USER CODE END EepromTask */
}
